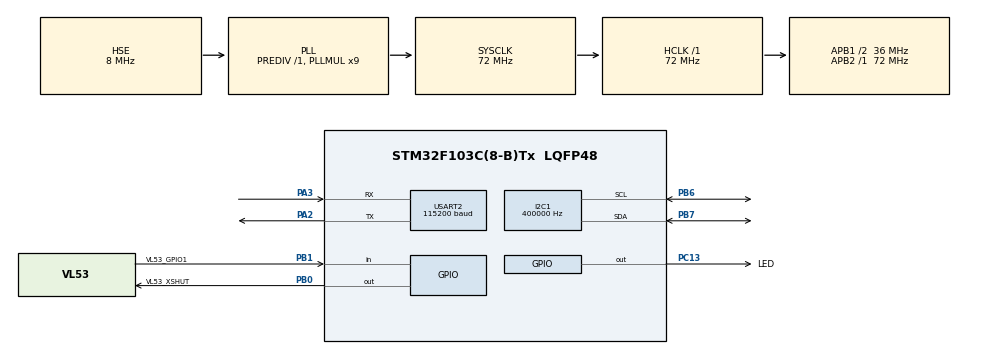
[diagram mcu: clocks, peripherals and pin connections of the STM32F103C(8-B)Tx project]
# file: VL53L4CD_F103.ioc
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I2C1.ClockSpeed=400000
Mcu.Family=STM32F1
Mcu.Name=STM32F103C(8-B)Tx
Mcu.Package=LQFP48
NVIC.PriorityGroup=NVIC_PRIORITYGROUP_4
PA13.Mode=Serial_Wire
PA13.Signal=SYS_JTMS-SWDIO
PA14.Mode=Serial_Wire
PA14.Signal=SYS_JTCK-SWCLK
PA2.Mode=Asynchronous
PA2.Signal=USART2_TX
PA3.Mode=Asynchronous
PA3.Signal=USART2_RX
PB6.Mode=I2C
PB6.Signal=I2C1_SCL
PB7.Mode=I2C
PB7.Signal=I2C1_SDA
PB0.GPIO_Label=VL53_XSHUT
PB0.PinState=GPIO_PIN_RESET
PB0.Signal=GPIO_Output
PB1.GPIO_Label=VL53_GPIO1
PB1.Signal=GPIO_Input
PC13-TAMPER-RTC.GPIO_Label=LED
PC13-TAMPER-RTC.PinState=GPIO_PIN_SET
PC13-TAMPER-RTC.Signal=GPIO_Output
PD0-OSC_IN.Mode=HSE-External-Oscillator
PD0-OSC_IN.Signal=RCC_OSC_IN
PD1-OSC_OUT.Mode=HSE-External-Oscillator
PD1-OSC_OUT.Signal=RCC_OSC_OUT
ProjectManager.HeapSize=0x200
ProjectManager.StackSize=0x400
ProjectManager.TargetToolchain=STM32CubeIDE
RCC.AHBFreq_Value=72000000
RCC.APB1CLKDivider=RCC_HCLK_DIV2
RCC.APB1Freq_Value=36000000
RCC.APB1TimFreq_Value=72000000
RCC.APB2Freq_Value=72000000
RCC.APB2TimFreq_Value=72000000
RCC.HCLKFreq_Value=72000000
RCC.PLLMUL=RCC_PLL_MUL9
RCC.PLLSourceVirtual=RCC_PLLSOURCE_HSE
RCC.SYSCLKFreq_VALUE=72000000
RCC.SYSCLKSource=RCC_SYSCLKSOURCE_PLLCLK
RCC.USBFreq_Value=72000000
USART2.BaudRate=115200
USART2.VirtualMode=VM_ASYNC
board=custom

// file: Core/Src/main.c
/* USER CODE BEGIN Header */
/**
  ******************************************************************************
  * @file           : main.c
  * @brief          : VL53L4CD standalone application entry point
  ******************************************************************************
  */
/* USER CODE END Header */

#include "main.h"
#include "gpio.h"
#include "i2c.h"
#include "usart.h"

/* USER CODE BEGIN Includes */
#include "app.h"
/* USER CODE END Includes */

void SystemClock_Config(void);

int main(void)
{
    HAL_Init();
    SystemClock_Config();

    MX_GPIO_Init();
    MX_I2C1_Init();
    MX_USART2_UART_Init();

    /* USER CODE BEGIN 2 */
    App_Init();
    /* USER CODE END 2 */

    /* Infinite loop */
    /* USER CODE BEGIN WHILE */
    while (1) {
        App_Loop();
        /* USER CODE END WHILE */

    }
}

void SystemClock_Config(void)
{
    RCC_OscInitTypeDef RCC_OscInitStruct = {0};
    RCC_ClkInitTypeDef RCC_ClkInitStruct = {0};

    RCC_OscInitStruct.OscillatorType = RCC_OSCILLATORTYPE_HSE;
    RCC_OscInitStruct.HSEState = RCC_HSE_ON;
    RCC_OscInitStruct.HSEPredivValue = RCC_HSE_PREDIV_DIV1;
    RCC_OscInitStruct.HSIState = RCC_HSI_ON;
    RCC_OscInitStruct.PLL.PLLState = RCC_PLL_ON;
    RCC_OscInitStruct.PLL.PLLSource = RCC_PLLSOURCE_HSE;
    RCC_OscInitStruct.PLL.PLLMUL = RCC_PLL_MUL9;
    if (HAL_RCC_OscConfig(&RCC_OscInitStruct) != HAL_OK) {
        Error_Handler();
    }

    RCC_ClkInitStruct.ClockType = RCC_CLOCKTYPE_HCLK
                                | RCC_CLOCKTYPE_SYSCLK
                                | RCC_CLOCKTYPE_PCLK1
                                | RCC_CLOCKTYPE_PCLK2;
    RCC_ClkInitStruct.SYSCLKSource = RCC_SYSCLKSOURCE_PLLCLK;
    RCC_ClkInitStruct.AHBCLKDivider = RCC_SYSCLK_DIV1;
    RCC_ClkInitStruct.APB1CLKDivider = RCC_HCLK_DIV2;
    RCC_ClkInitStruct.APB2CLKDivider = RCC_HCLK_DIV1;
    if (HAL_RCC_ClockConfig(&RCC_ClkInitStruct, FLASH_LATENCY_2) != HAL_OK) {
        Error_Handler();
    }
}

void Error_Handler(void)
{
    /* USER CODE BEGIN Error_Handler_Debug */
    while (1) {
        HAL_GPIO_TogglePin(LED_GPIO_Port, LED_Pin);
        for (volatile uint32_t delay = 0U; delay < 500000U; ++delay) {
            __NOP();
        }
    }
    /* USER CODE END Error_Handler_Debug */
}
